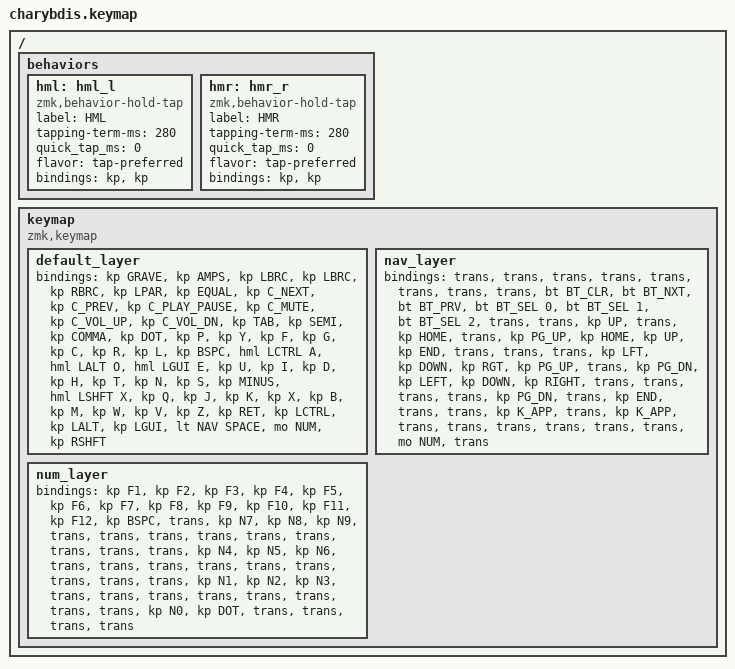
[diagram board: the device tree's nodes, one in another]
#include <behaviors.dtsi>
#include <dt-bindings/zmk/keys.h>
#include <dt-bindings/zmk/bt.h>

#define DEFAULT 0
#define NAV 1
#define NUM 2

/ {
    behaviors {
        hml: hml_l {
            compatible = "zmk,behavior-hold-tap";
            label = "HML";
            #binding-cells = <2>;
            tapping-term-ms = <280>;
            quick_tap_ms = <0>;
            flavor = "tap-preferred";
            bindings = <&kp>, <&kp>;
        };

        hmr: hmr_r {
            compatible = "zmk,behavior-hold-tap";
            label = "HMR";
            #binding-cells = <2>;
            tapping-term-ms = <280>;
            quick_tap_ms = <0>;
            flavor = "tap-preferred";
            bindings = <&kp>, <&kp>;
        };
    };

    keymap {
        compatible = "zmk,keymap";

        default_layer {
            bindings = <
                &kp GRAVE     &kp AMPS      &kp LBRC  &kp LBRC      &kp RBRC  &kp LPAR  &kp EQUAL    &kp C_NEXT   &kp C_PREV  &kp C_PLAY_PAUSE  &kp C_MUTE &kp C_VOL_UP  &kp C_VOL_DN
                &kp TAB       &kp SEMI      &kp COMMA &kp DOT       &kp P     &kp Y        &kp F        &kp G       &kp C       &kp R             &kp L      &kp BSPC
                &hml LCTRL A  &hml LALT O   &hml LGUI E  &kp U         &kp I        &kp D        &kp H       &kp T       &kp N             &kp S      &kp MINUS
                &hml LSHFT X  &kp Q         &kp J     &kp K         &kp X        &kp B        &kp M       &kp W       &kp V             &kp Z      &kp RET
                                           &kp LCTRL &kp LALT      &kp LGUI     &lt NAV SPACE &mo NUM      &kp RSHFT
            >;
        };

        nav_layer {
            bindings = <
                &trans &trans &trans    &trans &trans  &trans &trans    &trans &bt BT_CLR  &bt BT_NXT  &bt BT_PRV  &bt BT_SEL 0  &bt BT_SEL 1  &bt BT_SEL 2
                &trans &trans &kp UP    &trans &kp HOME  &trans    &kp PG_UP  &kp HOME      &kp UP      &kp END     &trans        &trans
                &trans &kp LFT &kp DOWN  &kp RGT  &kp PG_UP &trans    &kp PG_DN  &kp LEFT      &kp DOWN    &kp RIGHT   &trans        &trans
                &trans &trans &kp PG_DN &trans &kp END   &trans    &trans    &kp K_APP     &trans      &kp K_APP   &trans        &trans
                                        &trans &trans    &trans    &trans    &mo NUM       &trans
            >;
        };

        num_layer {
            bindings = <
                &kp F1  &kp F2  &kp F3  &kp F4  &kp F5  &kp F6  &kp F7  &kp F8  &kp F9  &kp F10 &kp F11 &kp F12  &kp BSPC
                &trans  &kp N7  &kp N8  &kp N9  &trans &trans &trans &trans &trans &trans &trans &trans
                &trans  &kp N4  &kp N5  &kp N6  &trans &trans &trans &trans &trans &trans &trans &trans
                &trans  &kp N1  &kp N2  &kp N3  &trans &trans &trans &trans &trans &trans &trans &trans
                               &kp N0  &kp DOT &trans &trans &trans &trans
            >;
        };
    };
};
